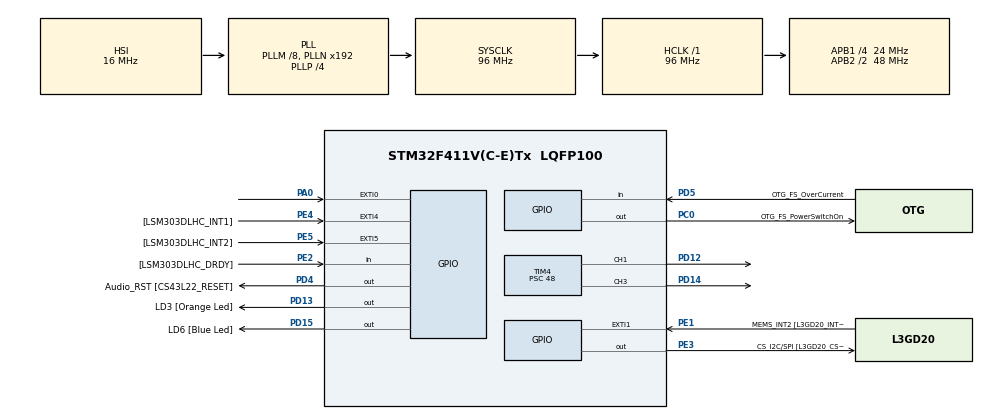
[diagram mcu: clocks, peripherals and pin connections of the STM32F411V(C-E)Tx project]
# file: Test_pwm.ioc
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Mcu.Family=STM32F4
Mcu.Name=STM32F411V(C-E)Tx
Mcu.Package=LQFP100
NVIC.PriorityGroup=NVIC_PRIORITYGROUP_0
PA0-WKUP.GPIO_ModeDefaultEXTI=GPIO_MODE_EVT_RISING
PA0-WKUP.Signal=GPXTI0
PA10.GPIO_Label=OTG_FS_ID
PA10.Signal=USB_OTG_FS_ID
PA11.GPIO_Label=OTG_FS_DM
PA11.Signal=USB_OTG_FS_DM
PA12.GPIO_Label=OTG_FS_DP
PA12.Signal=USB_OTG_FS_DP
PA13.GPIO_Label=SWDIO
PA13.Signal=SYS_JTMS-SWDIO
PA14.GPIO_Label=SWCLK
PA14.Signal=SYS_JTCK-SWCLK
PA4.GPIO_Label=I2S3_WS [CS43L22_LRCK]
PA4.GPIO_Mode=GPIO_MODE_AF_PP
PA4.GPIO_PuPd=GPIO_NOPULL
PA4.GPIO_Speed=GPIO_SPEED_LOW
PA4.Signal=I2S3_WS
PA5.GPIO_Label=SPI1_SCK [L3GD20_SC/SPC]
PA5.Signal=SPI1_SCK
PA6.GPIO_Label=SPI1_MISO [L3GD20_AS0/SDO]
PA6.Signal=SPI1_MISO
PA7.GPIO_Label=SPI1_MOSI [L3GD20_SDA/SDI/SDO]
PA7.Signal=SPI1_MOSI
PA9.GPIO_Label=VBUS_FS
PA9.Signal=USB_OTG_FS_VBUS
PB10.GPIO_Label=CLK_IN [MP45DT02_CLK]
PB10.Signal=I2S2_CK
PB12.Signal=I2S2_WS
PB3.GPIO_Label=SWO
PB3.Signal=SYS_JTDO-SWO
PB6.GPIO_Label=Audio_SCL [CS43L22_SCL]
PB6.GPIO_Mode=GPIO_MODE_AF_OD
PB6.GPIO_PuPd=GPIO_NOPULL
PB6.GPIO_Speed=GPIO_SPEED_LOW
PB6.Signal=I2C1_SCL
PB9.GPIO_Label=Audio_SDA [CS43L22_SDA]
PB9.GPIO_Mode=GPIO_MODE_AF_OD
PB9.GPIO_PuPd=GPIO_NOPULL
PB9.GPIO_Speed=GPIO_SPEED_LOW
PB9.Signal=I2C1_SDA
PC0.GPIO_Label=OTG_FS_PowerSwitchOn
PC0.Signal=GPIO_Output
PC10.GPIO_Label=I2S3_SCK [CS43L22_SCLK]
PC10.GPIO_Mode=GPIO_MODE_AF_PP
PC10.GPIO_PuPd=GPIO_NOPULL
PC10.GPIO_Speed=GPIO_SPEED_LOW
PC10.Signal=I2S3_CK
PC12.GPIO_Label=I2S3_SD [CS43L22_SDIN]
PC12.GPIO_Mode=GPIO_MODE_AF_PP
PC12.GPIO_PuPd=GPIO_NOPULL
PC12.GPIO_Speed=GPIO_SPEED_LOW
PC12.Signal=I2S3_SD
PC14-OSC32_IN.GPIO_Label=PC14-OSC32_IN
PC14-OSC32_IN.Signal=RCC_OSC32_IN
PC15-OSC32_OUT.GPIO_Label=PC15-OSC32_OUT
PC15-OSC32_OUT.Signal=RCC_OSC32_OUT
PC3.GPIO_Label=PDM_OUT [MP45DT02_DOUT]
PC3.Signal=I2S2_SD
PC7.GPIO_Label=I2S3_MCK [CS43L22_MCLK]
PC7.GPIO_Mode=GPIO_MODE_AF_PP
PC7.GPIO_PuPd=GPIO_NOPULL
PC7.GPIO_Speed=GPIO_SPEED_LOW
PC7.Signal=I2S3_MCK
PD12.Signal=S_TIM4_CH1
PD13.GPIO_Label=LD3 [Orange Led]
PD13.GPIO_PuPd=GPIO_NOPULL
PD13.GPIO_Speed=GPIO_SPEED_LOW
PD13.Signal=GPIO_Output
PD14.Signal=S_TIM4_CH3
PD15.GPIO_Label=LD6 [Blue Led]
PD15.GPIO_PuPd=GPIO_NOPULL
PD15.GPIO_Speed=GPIO_SPEED_LOW
PD15.Signal=GPIO_Output
PD4.GPIO_Label=Audio_RST [CS43L22_RESET]
PD4.Signal=GPIO_Output
PD5.GPIO_Label=OTG_FS_OverCurrent
PD5.Signal=GPIO_Input
PE1.GPIO_Label=MEMS_INT2 [L3GD20_INT2]
PE1.GPIO_ModeDefaultEXTI=GPIO_MODE_EVT_RISING
PE1.Signal=GPXTI1
PE2.GPIO_Label=[LSM303DLHC_DRDY]
PE2.Signal=GPIO_Input
PE3.GPIO_Label=CS_I2C/SPI [L3GD20_CS_I2C/SPI]
PE3.Signal=GPIO_Output
PE4.GPIO_Label=[LSM303DLHC_INT1]
PE4.GPIO_ModeDefaultEXTI=GPIO_MODE_EVT_RISING
PE4.Signal=GPXTI4
PE5.GPIO_Label=[LSM303DLHC_INT2]
PE5.GPIO_ModeDefaultEXTI=GPIO_MODE_EVT_RISING
PE5.Signal=GPXTI5
PH0\ -\ OSC_IN.GPIO_Label=PH0-OSC_IN
PH0\ -\ OSC_IN.Signal=RCC_OSC_IN
PH1\ -\ OSC_OUT.GPIO_Label=PH1-OSC_OUT
PH1\ -\ OSC_OUT.Signal=RCC_OSC_OUT
ProjectManager.HeapSize=0x400
ProjectManager.StackSize=0x200
ProjectManager.TargetToolchain=TrueSTUDIO
RCC.48MHZClocksFreq_Value=48000000
RCC.AHBFreq_Value=96000000
RCC.APB1CLKDivider=RCC_HCLK_DIV4
RCC.APB1Freq_Value=24000000
RCC.APB1TimFreq_Value=48000000
RCC.APB2CLKDivider=RCC_HCLK_DIV2
RCC.APB2Freq_Value=48000000
RCC.APB2TimFreq_Value=96000000
RCC.CortexFreq_Value=96000000
RCC.HCLKFreq_Value=96000000
RCC.HSE_VALUE=8000000
RCC.HSI_VALUE=16000000
RCC.LSE_VALUE=32768
RCC.PLLI2SM=5
RCC.PLLI2SN=200
RCC.PLLM=8
RCC.PLLP=RCC_PLLP_DIV4
RCC.PLLQ=8
RCC.SYSCLKFreq_VALUE=96000000
RCC.SYSCLKSource=RCC_SYSCLKSOURCE_PLLCLK
RCC.VCOOutputFreq_Value=384000000
SH.S_TIM4_CH1.0=TIM4_CH1,PWM Generation1 CH1
SH.S_TIM4_CH3.0=TIM4_CH3,PWM Generation3 CH3
TIM4.Channel-PWM\ Generation3\ CH3=TIM_CHANNEL_3
TIM4.Period=200
TIM4.Prescaler=48
VP_TIM4_VS_ClockSourceINT.Mode=Internal
board=STM32F411E-DISCO

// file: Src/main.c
/**
  ******************************************************************************
  * File Name          : main.c
  * Description        : Main program body
  ******************************************************************************
  *
  * COPYRIGHT(c) 2016 STMicroelectronics
  *
  * Redistribution and use in source and binary forms, with or without modification,
  * are permitted provided that the following conditions are met:
  *   1. Redistributions of source code must retain the above copyright notice,
  *      this list of conditions and the following disclaimer.
  *   2. Redistributions in binary form must reproduce the above copyright notice,
  *      this list of conditions and the following disclaimer in the documentation
  *      and/or other materials provided with the distribution.
  *   3. Neither the name of STMicroelectronics nor the names of its contributors
  *      may be used to endorse or promote products derived from this software
  *      without specific prior written permission.
  *
  * THIS SOFTWARE IS PROVIDED BY THE COPYRIGHT HOLDERS AND CONTRIBUTORS "AS IS"
  * AND ANY EXPRESS OR IMPLIED WARRANTIES, INCLUDING, BUT NOT LIMITED TO, THE
  * IMPLIED WARRANTIES OF MERCHANTABILITY AND FITNESS FOR A PARTICULAR PURPOSE ARE
  * DISCLAIMED. IN NO EVENT SHALL THE COPYRIGHT HOLDER OR CONTRIBUTORS BE LIABLE
  * FOR ANY DIRECT, INDIRECT, INCIDENTAL, SPECIAL, EXEMPLARY, OR CONSEQUENTIAL
  * DAMAGES (INCLUDING, BUT NOT LIMITED TO, PROCUREMENT OF SUBSTITUTE GOODS OR
  * SERVICES; LOSS OF USE, DATA, OR PROFITS; OR BUSINESS INTERRUPTION) HOWEVER
  * CAUSED AND ON ANY THEORY OF LIABILITY, WHETHER IN CONTRACT, STRICT LIABILITY,
  * OR TORT (INCLUDING NEGLIGENCE OR OTHERWISE) ARISING IN ANY WAY OUT OF THE USE
  * OF THIS SOFTWARE, EVEN IF ADVISED OF THE POSSIBILITY OF SUCH DAMAGE.
  *
  ******************************************************************************
  */
#include "stm32f4xx_hal.h"

TIM_HandleTypeDef htim4;

int pwmgreen = 0;
int pwmred = 0;
/* USER CODE BEGIN PV */
/* Private variables ---------------------------------------------------------*/

/* USER CODE END PV */

void SystemClock_Config(void);
static void MX_GPIO_Init(void);
static void MX_TIM4_Init(void);

void HAL_TIM_MspPostInit(TIM_HandleTypeDef *htim);

/* USER CODE BEGIN PFP */
/* Private function prototypes -----------------------------------------------*/

/* USER CODE END PFP */

int main(void)
{

  /* MCU Configuration----------------------------------------------------------*/

  /* Reset of all peripherals, Initializes the Flash interface and the Systick. */
  HAL_Init();

  /* Configure the system clock */
  SystemClock_Config();

  /* Initialize all configured peripherals */
  MX_GPIO_Init();
  MX_TIM4_Init();

  /* USER CODE BEGIN 2 */

  	  HAL_TIM_PWM_Start(&htim4,TIM_CHANNEL_3);
  	  HAL_TIM_PWM_Start(&htim4,TIM_CHANNEL_1);

  /* USER CODE END 2 */

  /* Infinite loop */
  while (1)
  {

	  for(pwmgreen = 0; pwmgreen < 200;pwmgreen++)
	  {
		  __HAL_TIM_SetCompare(&htim4,TIM_CHANNEL_3,pwmgreen);
		  HAL_Delay(10);
	  }
	  for(pwmred = 0; pwmred < 200;pwmred++)
	  	  {
	  		  __HAL_TIM_SetCompare(&htim4,TIM_CHANNEL_1,pwmred);
	  		  HAL_Delay(10);
	  	  }
  }

}

/** System Clock Configuration
*/
void SystemClock_Config(void)
{

  RCC_OscInitTypeDef RCC_OscInitStruct;
  RCC_ClkInitTypeDef RCC_ClkInitStruct;

  __PWR_CLK_ENABLE();

  __HAL_PWR_VOLTAGESCALING_CONFIG(PWR_REGULATOR_VOLTAGE_SCALE1);

  RCC_OscInitStruct.OscillatorType = RCC_OSCILLATORTYPE_HSI;
  RCC_OscInitStruct.HSIState = RCC_HSI_ON;
  RCC_OscInitStruct.HSICalibrationValue = 16;
  RCC_OscInitStruct.PLL.PLLState = RCC_PLL_ON;
  RCC_OscInitStruct.PLL.PLLSource = RCC_PLLSOURCE_HSI;
  RCC_OscInitStruct.PLL.PLLM = 8;
  RCC_OscInitStruct.PLL.PLLN = 192;
  RCC_OscInitStruct.PLL.PLLP = RCC_PLLP_DIV4;
  RCC_OscInitStruct.PLL.PLLQ = 8;
  HAL_RCC_OscConfig(&RCC_OscInitStruct);

  RCC_ClkInitStruct.ClockType = RCC_CLOCKTYPE_HCLK|RCC_CLOCKTYPE_SYSCLK
                              |RCC_CLOCKTYPE_PCLK1|RCC_CLOCKTYPE_PCLK2;
  RCC_ClkInitStruct.SYSCLKSource = RCC_SYSCLKSOURCE_PLLCLK;
  RCC_ClkInitStruct.AHBCLKDivider = RCC_SYSCLK_DIV1;
  RCC_ClkInitStruct.APB1CLKDivider = RCC_HCLK_DIV4;
  RCC_ClkInitStruct.APB2CLKDivider = RCC_HCLK_DIV2;
  HAL_RCC_ClockConfig(&RCC_ClkInitStruct, FLASH_LATENCY_3);

  HAL_SYSTICK_Config(HAL_RCC_GetHCLKFreq()/1000);

  HAL_SYSTICK_CLKSourceConfig(SYSTICK_CLKSOURCE_HCLK);

  /* SysTick_IRQn interrupt configuration */
  HAL_NVIC_SetPriority(SysTick_IRQn, 0, 0);
}

/* TIM4 init function */
void MX_TIM4_Init(void)
{

  TIM_ClockConfigTypeDef sClockSourceConfig;
  TIM_MasterConfigTypeDef sMasterConfig;
  TIM_OC_InitTypeDef sConfigOC;

  htim4.Instance = TIM4;
  htim4.Init.Prescaler = 48;
  htim4.Init.CounterMode = TIM_COUNTERMODE_UP;
  htim4.Init.Period = 200;
  htim4.Init.ClockDivision = TIM_CLOCKDIVISION_DIV1;
  HAL_TIM_Base_Init(&htim4);

  sClockSourceConfig.ClockSource = TIM_CLOCKSOURCE_INTERNAL;
  HAL_TIM_ConfigClockSource(&htim4, &sClockSourceConfig);

  HAL_TIM_PWM_Init(&htim4);

  sMasterConfig.MasterOutputTrigger = TIM_TRGO_RESET;
  sMasterConfig.MasterSlaveMode = TIM_MASTERSLAVEMODE_DISABLE;
  HAL_TIMEx_MasterConfigSynchronization(&htim4, &sMasterConfig);

  sConfigOC.OCMode = TIM_OCMODE_PWM1;
  sConfigOC.Pulse = 0;
  sConfigOC.OCPolarity = TIM_OCPOLARITY_HIGH;
  sConfigOC.OCFastMode = TIM_OCFAST_DISABLE;
  HAL_TIM_PWM_ConfigChannel(&htim4, &sConfigOC, TIM_CHANNEL_1);

  HAL_TIM_PWM_ConfigChannel(&htim4, &sConfigOC, TIM_CHANNEL_3);

  HAL_TIM_MspPostInit(&htim4);

}

/** Configure pins as
        * Analog
        * Input
        * Output
        * EVENT_OUT
        * EXTI
     PC3   ------> I2S2_SD
     PA4   ------> I2S3_WS
     PA5   ------> SPI1_SCK
     PA6   ------> SPI1_MISO
     PA7   ------> SPI1_MOSI
     PB10   ------> I2S2_CK
     PB12   ------> I2S2_WS
     PC7   ------> I2S3_MCK
     PA9   ------> USB_OTG_FS_VBUS
     PA10   ------> USB_OTG_FS_ID
     PA11   ------> USB_OTG_FS_DM
     PA12   ------> USB_OTG_FS_DP
     PC10   ------> I2S3_CK
     PC12   ------> I2S3_SD
     PB6   ------> I2C1_SCL
     PB9   ------> I2C1_SDA
*/
void MX_GPIO_Init(void)
{

  GPIO_InitTypeDef GPIO_InitStruct;

  /* GPIO Ports Clock Enable */
  __GPIOE_CLK_ENABLE();
  __GPIOC_CLK_ENABLE();
  __GPIOH_CLK_ENABLE();
  __GPIOA_CLK_ENABLE();
  __GPIOB_CLK_ENABLE();
  __GPIOD_CLK_ENABLE();

  /*Configure GPIO pin : PE2 */
  GPIO_InitStruct.Pin = GPIO_PIN_2;
  GPIO_InitStruct.Mode = GPIO_MODE_INPUT;
  GPIO_InitStruct.Pull = GPIO_NOPULL;
  HAL_GPIO_Init(GPIOE, &GPIO_InitStruct);

  /*Configure GPIO pin : CS_I2C_SPI_Pin */
  GPIO_InitStruct.Pin = CS_I2C_SPI_Pin;
  GPIO_InitStruct.Mode = GPIO_MODE_OUTPUT_PP;
  GPIO_InitStruct.Pull = GPIO_NOPULL;
  GPIO_InitStruct.Speed = GPIO_SPEED_LOW;
  HAL_GPIO_Init(CS_I2C_SPI_GPIO_Port, &GPIO_InitStruct);

  /*Configure GPIO pins : PE4 PE5 MEMS_INT2_Pin */
  GPIO_InitStruct.Pin = GPIO_PIN_4|GPIO_PIN_5|MEMS_INT2_Pin;
  GPIO_InitStruct.Mode = GPIO_MODE_EVT_RISING;
  GPIO_InitStruct.Pull = GPIO_NOPULL;
  HAL_GPIO_Init(GPIOE, &GPIO_InitStruct);

  /*Configure GPIO pin : OTG_FS_PowerSwitchOn_Pin */
  GPIO_InitStruct.Pin = OTG_FS_PowerSwitchOn_Pin;
  GPIO_InitStruct.Mode = GPIO_MODE_OUTPUT_PP;
  GPIO_InitStruct.Pull = GPIO_NOPULL;
  GPIO_InitStruct.Speed = GPIO_SPEED_LOW;
  HAL_GPIO_Init(OTG_FS_PowerSwitchOn_GPIO_Port, &GPIO_InitStruct);

  /*Configure GPIO pin : PDM_OUT_Pin */
  GPIO_InitStruct.Pin = PDM_OUT_Pin;
  GPIO_InitStruct.Mode = GPIO_MODE_AF_PP;
  GPIO_InitStruct.Pull = GPIO_NOPULL;
  GPIO_InitStruct.Speed = GPIO_SPEED_LOW;
  GPIO_InitStruct.Alternate = GPIO_AF5_SPI2;
  HAL_GPIO_Init(PDM_OUT_GPIO_Port, &GPIO_InitStruct);

  /*Configure GPIO pin : PA0 */
  GPIO_InitStruct.Pin = GPIO_PIN_0;
  GPIO_InitStruct.Mode = GPIO_MODE_EVT_RISING;
  GPIO_InitStruct.Pull = GPIO_NOPULL;
  HAL_GPIO_Init(GPIOA, &GPIO_InitStruct);

  /*Configure GPIO pin : PA4 */
  GPIO_InitStruct.Pin = GPIO_PIN_4;
  GPIO_InitStruct.Mode = GPIO_MODE_AF_PP;
  GPIO_InitStruct.Pull = GPIO_NOPULL;
  GPIO_InitStruct.Speed = GPIO_SPEED_LOW;
  GPIO_InitStruct.Alternate = GPIO_AF6_SPI3;
  HAL_GPIO_Init(GPIOA, &GPIO_InitStruct);

  /*Configure GPIO pins : PA5 PA6 PA7 */
  GPIO_InitStruct.Pin = GPIO_PIN_5|GPIO_PIN_6|GPIO_PIN_7;
  GPIO_InitStruct.Mode = GPIO_MODE_AF_PP;
  GPIO_InitStruct.Pull = GPIO_NOPULL;
  GPIO_InitStruct.Speed = GPIO_SPEED_HIGH;
  GPIO_InitStruct.Alternate = GPIO_AF5_SPI1;
  HAL_GPIO_Init(GPIOA, &GPIO_InitStruct);

  /*Configure GPIO pins : CLK_IN_Pin PB12 */
  GPIO_InitStruct.Pin = CLK_IN_Pin|GPIO_PIN_12;
  GPIO_InitStruct.Mode = GPIO_MODE_AF_PP;
  GPIO_InitStruct.Pull = GPIO_NOPULL;
  GPIO_InitStruct.Speed = GPIO_SPEED_LOW;
  GPIO_InitStruct.Alternate = GPIO_AF5_SPI2;
  HAL_GPIO_Init(GPIOB, &GPIO_InitStruct);

  /*Configure GPIO pins : LD3_Pin LD6_Pin Audio_RST_Pin */
  GPIO_InitStruct.Pin = LD3_Pin|LD6_Pin|Audio_RST_Pin;
  GPIO_InitStruct.Mode = GPIO_MODE_OUTPUT_PP;
  GPIO_InitStruct.Pull = GPIO_NOPULL;
  GPIO_InitStruct.Speed = GPIO_SPEED_LOW;
  HAL_GPIO_Init(GPIOD, &GPIO_InitStruct);

  /*Configure GPIO pins : PC7 I2S3_SCK_Pin PC12 */
  GPIO_InitStruct.Pin = GPIO_PIN_7|I2S3_SCK_Pin|GPIO_PIN_12;
  GPIO_InitStruct.Mode = GPIO_MODE_AF_PP;
  GPIO_InitStruct.Pull = GPIO_NOPULL;
  GPIO_InitStruct.Speed = GPIO_SPEED_LOW;
  GPIO_InitStruct.Alternate = GPIO_AF6_SPI3;
  HAL_GPIO_Init(GPIOC, &GPIO_InitStruct);

  /*Configure GPIO pin : VBUS_FS_Pin */
  GPIO_InitStruct.Pin = VBUS_FS_Pin;
  GPIO_InitStruct.Mode = GPIO_MODE_INPUT;
  GPIO_InitStruct.Pull = GPIO_NOPULL;
  HAL_GPIO_Init(VBUS_FS_GPIO_Port, &GPIO_InitStruct);

  /*Configure GPIO pins : OTG_FS_ID_Pin OTG_FS_DM_Pin OTG_FS_DP_Pin */
  GPIO_InitStruct.Pin = OTG_FS_ID_Pin|OTG_FS_DM_Pin|OTG_FS_DP_Pin;
  GPIO_InitStruct.Mode = GPIO_MODE_AF_PP;
  GPIO_InitStruct.Pull = GPIO_NOPULL;
  GPIO_InitStruct.Speed = GPIO_SPEED_HIGH;
  GPIO_InitStruct.Alternate = GPIO_AF10_OTG_FS;
  HAL_GPIO_Init(GPIOA, &GPIO_InitStruct);

  /*Configure GPIO pin : OTG_FS_OverCurrent_Pin */
  GPIO_InitStruct.Pin = OTG_FS_OverCurrent_Pin;
  GPIO_InitStruct.Mode = GPIO_MODE_INPUT;
  GPIO_InitStruct.Pull = GPIO_NOPULL;
  HAL_GPIO_Init(OTG_FS_OverCurrent_GPIO_Port, &GPIO_InitStruct);

  /*Configure GPIO pins : Audio_SCL_Pin Audio_SDA_Pin */
  GPIO_InitStruct.Pin = Audio_SCL_Pin|Audio_SDA_Pin;
  GPIO_InitStruct.Mode = GPIO_MODE_AF_OD;
  GPIO_InitStruct.Pull = GPIO_PULLUP;
  GPIO_InitStruct.Speed = GPIO_SPEED_LOW;
  GPIO_InitStruct.Alternate = GPIO_AF4_I2C1;
  HAL_GPIO_Init(GPIOB, &GPIO_InitStruct);

  /*Configure GPIO pin Output Level */
  HAL_GPIO_WritePin(CS_I2C_SPI_GPIO_Port, CS_I2C_SPI_Pin, GPIO_PIN_RESET);

  /*Configure GPIO pin Output Level */
  HAL_GPIO_WritePin(OTG_FS_PowerSwitchOn_GPIO_Port, OTG_FS_PowerSwitchOn_Pin, GPIO_PIN_RESET);

  /*Configure GPIO pin Output Level */
  HAL_GPIO_WritePin(GPIOD, LD3_Pin|LD6_Pin|Audio_RST_Pin, GPIO_PIN_RESET);

}

/************************ (C) COPYRIGHT STMicroelectronics *****END OF FILE****/
